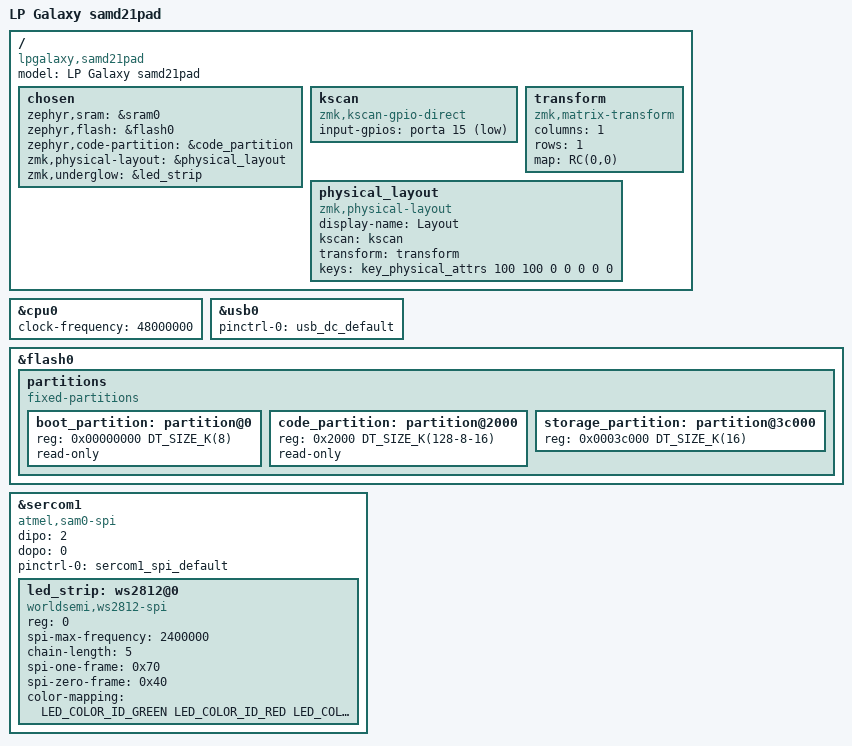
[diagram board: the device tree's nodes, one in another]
/*
 * Copyright (c) 2023 Pete Johanson
 *
 * SPDX-License-Identifier: Apache-2.0
 */

/dts-v1/;
#include <atmel/samd21.dtsi>
#include <atmel/samx2xx17.dtsi>
#include <dt-bindings/zmk/matrix_transform.h>
#include <dt-bindings/led/led.h>
#include "samd21pad-pinctrl.dtsi"
#include <physical_layouts.dtsi>

/ {
	model = "LP Galaxy samd21pad";
	compatible = "lpgalaxy,samd21pad";

	chosen {
		zephyr,sram = &sram0;
		zephyr,flash = &flash0;
		zephyr,code-partition = &code_partition;
		zmk,physical-layout = &physical_layout;
		zmk,underglow = &led_strip;
	};
	kscan: kscan {
		compatible = "zmk,kscan-gpio-direct";
		
		input-gpios
			= <&porta 15 (GPIO_ACTIVE_LOW | GPIO_PULL_UP)>
			;
	};

	transform: transform {
		compatible = "zmk,matrix-transform";
		columns = <1>;
		rows = <1>;
		map = <
		  RC(0,0)>;
	  };

	physical_layout: physical_layout {
        compatible = "zmk,physical-layout";
        display-name = "Layout";

        kscan = <&kscan>;
		transform = <&transform>;

        keys  //                     w   h    x    y     rot   rx   ry
            = <&key_physical_attrs 100 100    0    0       0    0    0>
            ;
    };

};

&cpu0 {
	clock-frequency = <48000000>;
};

zephyr_udc0: &usb0 {
        status = "okay";

        pinctrl-0 = <&usb_dc_default>;
        pinctrl-names = "default";
};

&flash0 {
	partitions {
		compatible = "fixed-partitions";
		#address-cells = <1>;
		#size-cells = <1>;

		boot_partition: partition@0 {
			reg = <0x00000000 DT_SIZE_K(8)>;
			read-only;
		};

		code_partition: partition@2000 {
			reg = <0x2000 DT_SIZE_K(128-8-16)>;
			read-only;
		};

		/*
		 * The final 16 KiB is reserved for the application.
		 * Storage partition may be used by FCB or LittleFS.
		 */
		storage_partition: partition@3c000 {
			reg = <0x0003c000 DT_SIZE_K(16)>;
		};
	};
};

/* Drives the on-board DotStar LED */
&sercom1 {
	status = "okay";
	compatible = "atmel,sam0-spi";
	dipo = <2>;
	dopo = <0>;
	#address-cells = <1>;
	#size-cells = <0>;

	pinctrl-0 = <&sercom1_spi_default>;
	pinctrl-names = "default";

	led_strip: ws2812@0 {
		compatible = "worldsemi,ws2812-spi";

		/* SPI */
		reg = <0>; /* ignored, but necessary for SPI bindings */
		spi-max-frequency = <2400000>;

		/* WS2812 */
		chain-length = <5>; /* LED strip length */
		spi-one-frame = <0x70>;
		spi-zero-frame = <0x40>;
		color-mapping = <LED_COLOR_ID_GREEN LED_COLOR_ID_RED LED_COLOR_ID_BLUE>;
	};
};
